# STM32F446 register map
File version: 1.1
CPU: CM4 r1p0, little endian, no MPU, no FPU, 4 interrupt priority bits
Registers are 32-bit, read-write, reset 0x0 unless marked. A register's access mark holds for its fields unless they carry their own. Offsets are from the block's base; lines under a group give offsets from that group; [hi:lo] are bit positions; {n}, {i} and the like mark numbered series; 'fields as' and 'values as' point back to an identical list; <NAME> marks a mode.

## Memory map
0x40040000 OTG_HS_GLOBAL size 0x400 — USB on the go high speed
0x40040400 OTG_HS_HOST size 0x400 — USB on the go high speed
0x40040800 OTG_HS_DEVICE size 0x400 — USB on the go high speed
0x40040E00 OTG_HS_PWRCLK size 0x400 — USB on the go high speed

## OTG_HS_HOST — USB on the go high speed
Base 0x40040400
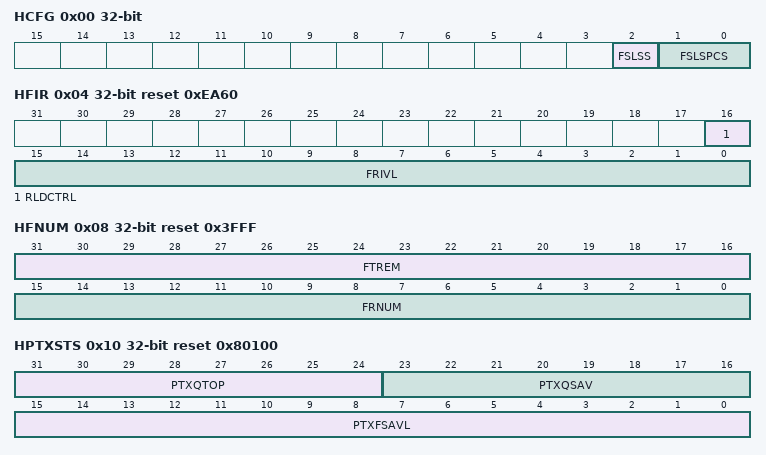
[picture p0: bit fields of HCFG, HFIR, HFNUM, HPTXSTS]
0x00 HCFG access per field — OTG host configuration register
  [2] FSLSS ro — FS- and LS-only support
  [1:0] FSLSPCS rw — FS/LS PHY clock select
0x04 HFIR reset 0xEA60 — OTG Host frame interval register
  [16] RLDCTRL — Reload control
  [15:0] FRIVL — Frame interval
0x08 HFNUM ro reset 0x3FFF — OTG host frame number/frame time remaining register
  [31:16] FTREM — Frame time remaining
  [15:0] FRNUM — Frame number
0x10 HPTXSTS ro reset 0x80100 — OTG host periodic transmit FIFO/queue status register
  [31:24] PTXQTOP — Top of the periodic transmit request queue
  [23:16] PTXQSAV — Periodic transmit request queue space available
  [15:0] PTXFSAVL — Periodic transmit data FIFO space available
0x14 HAINT ro — OTG host all channels interrupt register
  [15:0] HAINT — Channel interrupts
0x18 HAINTMSK — OTG host all channels interrupt mask register
  [15:0] HAINTM — Channel interrupt mask
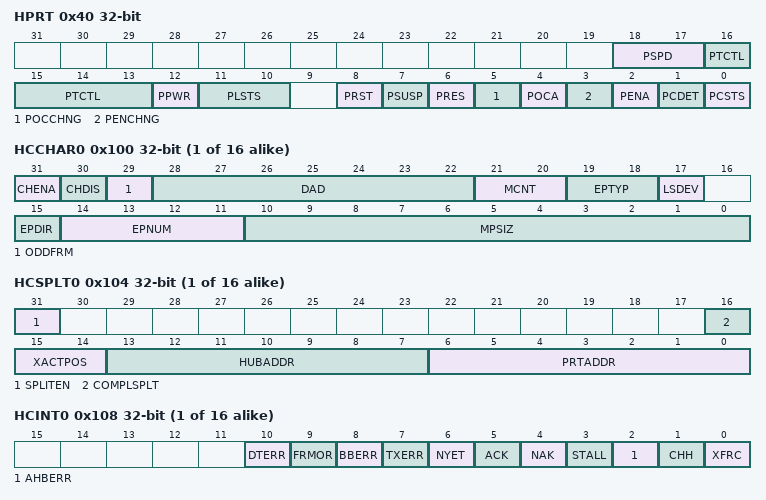
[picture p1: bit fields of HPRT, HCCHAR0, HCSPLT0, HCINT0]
0x40 HPRT access per field — OTG host port control and status register
  [18:17] PSPD ro — Port speed
  [16:13] PTCTL rw — Port test control
  [12] PPWR rw — Port power
  [11:10] PLSTS ro — Port line status
  [8] PRST rw — Port reset
  [7] PSUSP rw — Port suspend
  [6] PRES rw — Port resume
  [5] POCCHNG rw — Port overcurrent change
  [4] POCA ro — Port overcurrent active
  [3] PENCHNG rw — Port enable/disable change
  [2] PENA rw — Port enable
  [1] PCDET rw — Port connect detected
  [0] PCSTS ro — Port connect status
{0x100+0x20*i} HCCHAR{i} (i=0..15) — OTG host channel x characteristics register
  [31] CHENA — Channel enable
  [30] CHDIS — Channel disable
  [29] ODDFRM — Odd frame
  [28:22] DAD — Device address
  [21:20] MCNT — Multicount
  [19:18] EPTYP — Endpoint type
  [17] LSDEV — Low-speed device
  [15] EPDIR — Endpoint direction
  [14:11] EPNUM — Endpoint number
  [10:0] MPSIZ — Maximum packet size
{0x104+0x20*i} HCSPLT{i} (i=0..15) — OTG host channel x split control register
  [31] SPLITEN — Split enable
  [16] COMPLSPLT — Do complete split
  [15:14] XACTPOS — Transaction position
  [13:7] HUBADDR — Hub address
  [6:0] PRTADDR — Port address
{0x108+0x20*i} HCINT{i} (i=0..15) — OTG host channel x interrupt register
  [10] DTERR — Data toggle error
  [9] FRMOR — Frame overrun
  [8] BBERR — Babble error
  [7] TXERR — Transaction error
  [6] NYET — Not yet ready response received interrupt
  [5] ACK — ACK response received/transmitted interrupt
  [4] NAK — NAK response received interrupt
  [3] STALL — STALL response received interrupt
  [2] AHBERR — AHB error
  [1] CHH — Channel halted
  [0] XFRC — Transfer completed
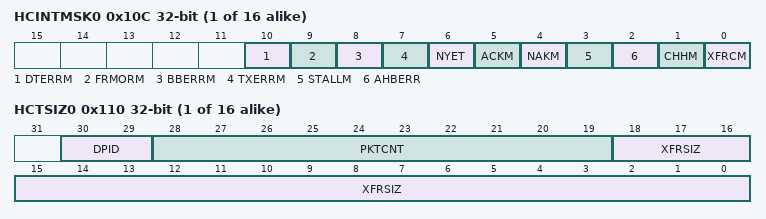
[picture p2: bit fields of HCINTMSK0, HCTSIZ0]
{0x10C+0x20*i} HCINTMSK{i} (i=0..15) — OTG host channel x interrupt mask register
  [10] DTERRM — Data toggle error mask
  [9] FRMORM — Frame overrun mask
  [8] BBERRM — Babble error mask
  [7] TXERRM — Transaction error mask
  [6] NYET — Not yet ready response received interrupt mask
  [5] ACKM — ACK response received/transmitted interrupt mask
  [4] NAKM — NAK response received interrupt mask
  [3] STALLM — STALL response received interrupt mask
  [2] AHBERR — AHB error
  [1] CHHM — Channel halted mask
  [0] XFRCM — Transfer completed mask
{0x110+0x20*i} HCTSIZ{i} (i=0..15) — OTG host channel x transfer size register
  [30:29] DPID — Data PID
  [28:19] PKTCNT — Packet count
  [18:0] XFRSIZ — Transfer size
{0x114+0x20*i} HCDMA{i} (i=0..15) — OTG host channel x DMA address register
  [31:0] DMAADDR — DMA address
